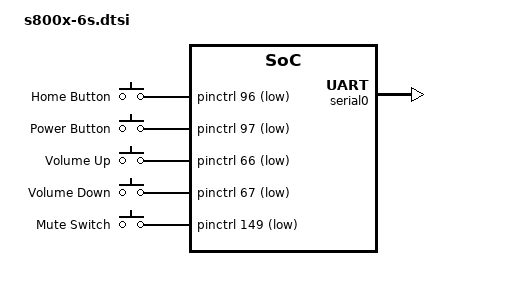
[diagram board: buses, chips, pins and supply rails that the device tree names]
// SPDX-License-Identifier: GPL-2.0+ OR MIT
/*
 * Apple iPhone 6S / 6S Plus common device tree
 *
 * Copyright (c) 2022, Konrad Dybcio <konrad.dybcio@somainline.org>
 */

#include <dt-bindings/input/input.h>

/ {
	gpio-keys {
		compatible = "gpio-keys";
		#address-cells = <1>;
		#size-cells = <0>;

		home {
			label = "Home Button";
			gpios = <&pinctrl 96 GPIO_ACTIVE_LOW>;
			linux,code = <KEY_LEFTMETA>;
		};

		power {
			label = "Power Button";
			gpios = <&pinctrl 97 GPIO_ACTIVE_LOW>;
			linux,code = <KEY_POWER>;
		};

		volume-up {
			label = "Volume Up";
			gpios = <&pinctrl 66 GPIO_ACTIVE_LOW>;
			linux,code = <KEY_VOLUMEUP>;
		};

		volume-down {
			label = "Volume Down";
			gpios = <&pinctrl 67 GPIO_ACTIVE_LOW>;
			linux,code = <KEY_VOLUMEDOWN>;
		};

		mute-switch {
			label = "Mute Switch";
			gpios = <&pinctrl 149 GPIO_ACTIVE_LOW>;
			linux,code = <KEY_MUTE>;
		};
	};
};

&serial0 {
	status = "okay";
};
